AUTOSAR XML (schema 00044)
package /ComponentTypes
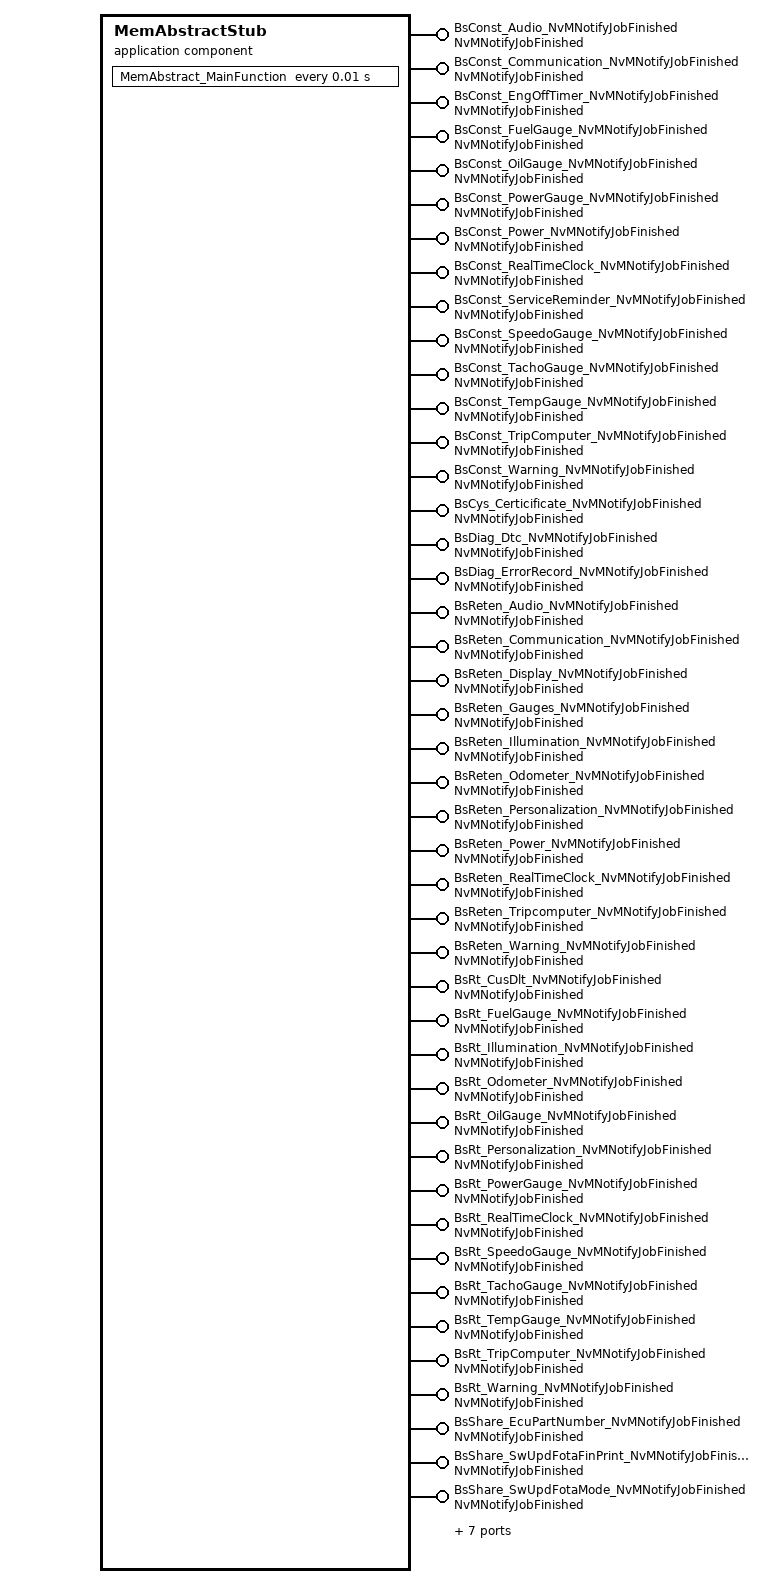
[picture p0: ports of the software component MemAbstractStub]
  application sw component type MemAbstractStub
    51 x provide port, all with server-com-spec{operation=JobFinished, queue-length=1}, provided-interface=NvMNotifyJobFinished:
      BsConst_Audio_NvMNotifyJobFinished
      BsConst_Communication_NvMNotifyJobFinished
      BsConst_EngOffTimer_NvMNotifyJobFinished
      BsConst_FuelGauge_NvMNotifyJobFinished
      BsConst_OilGauge_NvMNotifyJobFinished
      BsConst_PowerGauge_NvMNotifyJobFinished
      BsConst_Power_NvMNotifyJobFinished
      BsConst_RealTimeClock_NvMNotifyJobFinished
      BsConst_ServiceReminder_NvMNotifyJobFinished
      BsConst_SpeedoGauge_NvMNotifyJobFinished
      BsConst_TachoGauge_NvMNotifyJobFinished
      BsConst_TempGauge_NvMNotifyJobFinished
      BsConst_TripComputer_NvMNotifyJobFinished
      BsConst_Warning_NvMNotifyJobFinished
      BsCys_Certicificate_NvMNotifyJobFinished
      BsDiag_Dtc_NvMNotifyJobFinished
      BsDiag_ErrorRecord_NvMNotifyJobFinished
      BsReten_Audio_NvMNotifyJobFinished
      BsReten_Communication_NvMNotifyJobFinished
      BsReten_Display_NvMNotifyJobFinished
      BsReten_Gauges_NvMNotifyJobFinished
      BsReten_Illumination_NvMNotifyJobFinished
      BsReten_Odometer_NvMNotifyJobFinished
      BsReten_Personalization_NvMNotifyJobFinished
      BsReten_Power_NvMNotifyJobFinished
      BsReten_RealTimeClock_NvMNotifyJobFinished
      BsReten_Tripcomputer_NvMNotifyJobFinished
      BsReten_Warning_NvMNotifyJobFinished
      BsRt_CusDlt_NvMNotifyJobFinished
      BsRt_FuelGauge_NvMNotifyJobFinished
      BsRt_Illumination_NvMNotifyJobFinished
      BsRt_Odometer_NvMNotifyJobFinished
      BsRt_OilGauge_NvMNotifyJobFinished
      BsRt_Personalization_NvMNotifyJobFinished
      BsRt_PowerGauge_NvMNotifyJobFinished
      BsRt_RealTimeClock_NvMNotifyJobFinished
      BsRt_SpeedoGauge_NvMNotifyJobFinished
      BsRt_TachoGauge_NvMNotifyJobFinished
      BsRt_TempGauge_NvMNotifyJobFinished
      BsRt_TripComputer_NvMNotifyJobFinished
      BsRt_Warning_NvMNotifyJobFinished
      BsShare_EcuPartNumber_NvMNotifyJobFinished
      BsShare_SwUpdFotaFinPrint_NvMNotifyJobFinished
      BsShare_SwUpdFotaMode_NvMNotifyJobFinished
      BsShare_SwUpdFotaStatus_NvMNotifyJobFinished
      BsShare_SwUpdFotadecrypt_NvMNotifyJobFinished
      BsShare_SwUpdReflash_NvMNotifyJobFinished
      BsShare_VehicleConfig_NvMNotifyJobFinished
      BsShare_VisMeet_NvMNotifyJobFinished
      RefCys_Certicificate1_NvMNotifyJobFinished
      RefCys_Certicificate_NvMNotifyJobFinished
    94 x provide/require port:
      BsRt_SpeedoGauge_Element: nv-provide-com-spec{ram-block-init-value=8 x 0, rom-block-init-value=8 x 0, variable=Value}, nv-require-com-spec{init-value=8 x 0, variable=Value}, provided-required-interface=BsRt_SpeedoGauge_Element
      BsConst_Audio_Element: nv-provide-com-spec{ram-block-init-value=128 x 0, rom-block-init-value=128 x 0, variable=Value}, nv-require-com-spec{init-value=128 x 0, variable=Value}, provided-required-interface=BsConst_Audio_Element
      BsConst_EngOffTimer_Element: nv-provide-com-spec{ram-block-init-value=32 x 0, rom-block-init-value=32 x 0, variable=Value}, nv-require-com-spec{init-value=32 x 0, variable=Value}, provided-required-interface=BsConst_EngOffTimer_Element
      BsRt_OilGauge_Element: nv-provide-com-spec{ram-block-init-value=8 x 0, rom-block-init-value=8 x 0, variable=Value}, nv-require-com-spec{init-value=8 x 0, variable=Value}, provided-required-interface=BsRt_OilGauge_Element
      BsShare_EcuPartNumber_Element: nv-provide-com-spec{ram-block-init-value=61 x 0, rom-block-init-value=61 x 0, variable=Value}, nv-require-com-spec{init-value=61 x 0, variable=Value}, provided-required-interface=BsShare_EcuPartNumber_Element
      BsConst_PCB_Temperature_Sensor_Conv: nv-provide-com-spec{ram-block-init-value=[4095, 4095], rom-block-init-value=[4095, 4095], variable=Value}, nv-require-com-spec{init-value=[4095, 4095], variable=Value}, provided-required-interface=BsConst_PCB_Temperature_Sensor_Conv
      BsConst_Compensation_Line_Slope_m_SafeCopy2: nv-provide-com-spec{ram-block-init-value=44433, rom-block-init-value=44433, variable=Value}, nv-require-com-spec{init-value=44433, variable=Value}, provided-required-interface=BsConst_Compensation_Line_Slope_m_SafeCopy2
      BsConst_Temp_Threshold_Hysteresis_Derating_SafeCopy2: nv-provide-com-spec{ram-block-init-value=68, rom-block-init-value=68, variable=Value}, nv-require-com-spec{init-value=68, variable=Value}, provided-required-interface=BsConst_Temp_Threshold_Hysteresis_Derating_SafeCopy2
      BsConst_Compensation_Line_Shift_b: nv-provide-com-spec{ram-block-init-value=11, rom-block-init-value=11, variable=Value}, nv-require-com-spec{init-value=11, variable=Value}, provided-required-interface=BsConst_Compensation_Line_Shift_b
      BsConst_Temperature_Sensor_Conv_SafeCopy2: nv-provide-com-spec{ram-block-init-value=[4095, 4095], rom-block-init-value=[4095, 4095], variable=Value}, nv-require-com-spec{init-value=[4095, 4095], variable=Value}, provided-required-interface=BsConst_Temperature_Sensor_Conv_SafeCopy2
      BsShare_VisteonPartNumber: nv-provide-com-spec{ram-block-init-value=17 x 255, rom-block-init-value=17 x 255, variable=Value}, nv-require-com-spec{init-value=17 x 255, variable=Value}, provided-required-interface=BsShare_VisteonPartNumber
      BsConst_TempGauge_Element: nv-provide-com-spec{ram-block-init-value=64 x 0, rom-block-init-value=64 x 0, variable=Value}, nv-require-com-spec{init-value=64 x 0, variable=Value}, provided-required-interface=BsConst_TempGauge_Element
      BsConst_Lookup_Curve_HotSpot_Coef_X: nv-provide-com-spec{ram-block-init-value=[700, 710, 720, 730, 740, 750, 760], rom-block-init-value=[700, 710, 720, 730, 740, 750, 760], variable=Value}, nv-require-com-spec{init-value=[700, 710, 720, 730, 740, 750, 760], variable=Value}, provided-required-interface=BsConst_Lookup_Curve_HotSpot_Coef_X
      BsConst_Temperature_Sensor_Conv_SafeCopy1: nv-provide-com-spec{ram-block-init-value=[4095, 4095], rom-block-init-value=[4095, 4095], variable=Value}, nv-require-com-spec{init-value=[4095, 4095], variable=Value}, provided-required-interface=BsConst_Temperature_Sensor_Conv_SafeCopy1
      BsReten_Personalization_Element: nv-provide-com-spec{ram-block-init-value=100 x 0, rom-block-init-value=100 x 0, variable=Value}, nv-require-com-spec{init-value=100 x 0, variable=Value}, provided-required-interface=BsReten_Personalization_Element
      BsRt_RealTimeClock_Element: nv-provide-com-spec{ram-block-init-value=48 x 0, rom-block-init-value=48 x 0, variable=Value}, nv-require-com-spec{init-value=48 x 0, variable=Value}, provided-required-interface=BsRt_RealTimeClock_Element
      BsConst_Derating_Backlight_Disable: nv-provide-com-spec{ram-block-init-value=0, rom-block-init-value=0, variable=Value}, nv-require-com-spec{init-value=0, variable=Value}, provided-required-interface=BsConst_Derating_Backlight_Disable
      BsConst_Communication_Element: nv-provide-com-spec{ram-block-init-value=64 x 0, rom-block-init-value=64 x 0, variable=Value}, nv-require-com-spec{init-value=64 x 0, variable=Value}, provided-required-interface=BsConst_Communication_Element
      BsRt_PowerGauge_Element: nv-provide-com-spec{ram-block-init-value=32 x 0, rom-block-init-value=32 x 0, variable=Value}, nv-require-com-spec{init-value=32 x 0, variable=Value}, provided-required-interface=BsRt_PowerGauge_Element
      BsShare_VisMeet_EOLEntry_Element: nv-provide-com-spec{ram-block-init-value=65535, rom-block-init-value=65535, variable=Value}, nv-require-com-spec{init-value=65535, variable=Value}, provided-required-interface=BsShare_VisMeet_EOLEntry_Element
      BsConst_SpeedoGauge_Element: nv-provide-com-spec{ram-block-init-value=64 x 0, rom-block-init-value=64 x 0, variable=Value}, nv-require-com-spec{init-value=64 x 0, variable=Value}, provided-required-interface=BsConst_SpeedoGauge_Element
      BsCys_Certicificate_Element: nv-provide-com-spec{ram-block-init-value=64 x 0, rom-block-init-value=64 x 0, variable=Value}, nv-require-com-spec{init-value=64 x 0, variable=Value}, provided-required-interface=BsCys_Certicificate_Element
      BsReten_Tripcomputer_Element: nv-provide-com-spec{ram-block-init-value=100 x 0, rom-block-init-value=100 x 0, variable=Value}, nv-require-com-spec{init-value=100 x 0, variable=Value}, provided-required-interface=BsReten_Tripcomputer_Element
      BsRt_FuelGauge_Element: nv-provide-com-spec{ram-block-init-value=32 x 0, rom-block-init-value=32 x 0, variable=Value}, nv-require-com-spec{init-value=32 x 0, variable=Value}, provided-required-interface=BsRt_FuelGauge_Element
      BsConst_Lookup_Curve_HotSpot_Coef_Y: nv-provide-com-spec{ram-block-init-value=[8600, 7700, 6700, 5800, 4800, 3900, 3000], rom-block-init-value=[8600, 7700, 6700, 5800, 4800, 3900, 3000], variable=Value}, nv-require-com-spec{init-value=[8600, 7700, 6700, 5800, 4800, 3900, 3000], variable=Value}, provided-required-interface=BsConst_Lookup_Curve_HotSpot_Coef_Y
      BsShare_SwUpdFotadecrypt_Element: nv-provide-com-spec{ram-block-init-value=64 x 0, rom-block-init-value=64 x 0, variable=Value}, nv-require-com-spec{init-value=64 x 0, variable=Value}, provided-required-interface=BsShare_SwUpdFotadecrypt_Element
      BsRt_Personalization_Element: nv-provide-com-spec{ram-block-init-value=128 x 0, rom-block-init-value=128 x 0, variable=Value}, nv-require-com-spec{init-value=128 x 0, variable=Value}, provided-required-interface=BsRt_Personalization_Element
      BsShare_VehicleConfig_Element: nv-provide-com-spec{ram-block-init-value=256 x 0, rom-block-init-value=256 x 0, variable=Value}, nv-require-com-spec{init-value=256 x 0, variable=Value}, provided-required-interface=BsShare_VehicleConfig_Element
      BsConst_RealTimeClock_Element: nv-provide-com-spec{ram-block-init-value=48 x 0, rom-block-init-value=48 x 0, variable=Value}, nv-require-com-spec{init-value=48 x 0, variable=Value}, provided-required-interface=BsConst_RealTimeClock_Element
      BsConst_TripComputer_Element: nv-provide-com-spec{ram-block-init-value=64 x 0, rom-block-init-value=64 x 0, variable=Value}, nv-require-com-spec{init-value=64 x 0, variable=Value}, provided-required-interface=BsConst_TripComputer_Element
      BsRt_Odometer_Element: nv-provide-com-spec{ram-block-init-value=128 x 0, rom-block-init-value=128 x 0, variable=Value}, nv-require-com-spec{init-value=128 x 0, variable=Value}, provided-required-interface=BsRt_Odometer_Element
      BsConst_Temp_Threshold_Hysteresis_Derating: nv-provide-com-spec{ram-block-init-value=68, rom-block-init-value=68, variable=Value}, nv-require-com-spec{init-value=68, variable=Value}, provided-required-interface=BsConst_Temp_Threshold_Hysteresis_Derating
      BsShare_SMTManufacturingDate: nv-provide-com-spec{ram-block-init-value=[1, 1, 0], rom-block-init-value=[1, 1, 0], variable=Value}, nv-require-com-spec{init-value=[1, 1, 0], variable=Value}, provided-required-interface=BsShare_SMTManufacturingDate
      BsRt_TempGauge_Element: nv-provide-com-spec{ram-block-init-value=32 x 0, rom-block-init-value=32 x 0, variable=Value}, nv-require-com-spec{init-value=32 x 0, variable=Value}, provided-required-interface=BsRt_TempGauge_Element
      BsReten_Power_Element: nv-provide-com-spec{ram-block-init-value=100 x 0, rom-block-init-value=100 x 0, variable=Value}, nv-require-com-spec{init-value=100 x 0, variable=Value}, provided-required-interface=BsReten_Power_Element
      BsReten_Gauges_Element: nv-provide-com-spec{ram-block-init-value=100 x 0, rom-block-init-value=100 x 0, variable=Value}, nv-require-com-spec{init-value=100 x 0, variable=Value}, provided-required-interface=BsReten_Gauges_Element
      BsShare_SMTPlantNumber: nv-provide-com-spec{ram-block-init-value=[255, 255, 255], rom-block-init-value=[255, 255, 255], variable=Value}, nv-require-com-spec{init-value=[255, 255, 255], variable=Value}, provided-required-interface=BsShare_SMTPlantNumber
      BsConst_PCB_Temperature_Sensor_Conv_SafeCopy1: nv-provide-com-spec{ram-block-init-value=[4095, 4095], rom-block-init-value=[4095, 4095], variable=Value}, nv-require-com-spec{init-value=[4095, 4095], variable=Value}, provided-required-interface=BsConst_PCB_Temperature_Sensor_Conv_SafeCopy1
      BsConst_Lookup_Curve_HotSpot_Coef_Y_SafeCopy2: nv-provide-com-spec{ram-block-init-value=[8600, 7700, 6700, 5800, 4800, 3900, 3000], rom-block-init-value=[8600, 7700, 6700, 5800, 4800, 3900, 3000], variable=Value}, nv-require-com-spec{init-value=[8600, 7700, 6700, 5800, 4800, 3900, 3000], variable=Value}, provided-required-interface=BsConst_Lookup_Curve_HotSpot_Coef_Y_SafeCopy2
      BsConst_BsConst_Illumination_ReservedByte_SafeCopy2: nv-provide-com-spec{ram-block-init-value=28 x 0, rom-block-init-value=28 x 0, variable=Value}, nv-require-com-spec{init-value=28 x 0, variable=Value}, provided-required-interface=BsConst_BsConst_Illumination_ReservedByte_SafeCopy2
      BsRt_Warning_Element: nv-provide-com-spec{ram-block-init-value=32 x 0, rom-block-init-value=32 x 0, variable=Value}, nv-require-com-spec{init-value=32 x 0, variable=Value}, provided-required-interface=BsRt_Warning_Element
      BsReten_Warning_Element: nv-provide-com-spec{ram-block-init-value=100 x 0, rom-block-init-value=100 x 0, variable=Value}, nv-require-com-spec{init-value=100 x 0, variable=Value}, provided-required-interface=BsReten_Warning_Element
      BsShare_AssemblyPlantNumber: nv-provide-com-spec{ram-block-init-value=[255, 255, 255], rom-block-init-value=[255, 255, 255], variable=Value}, nv-require-com-spec{init-value=[255, 255, 255], variable=Value}, provided-required-interface=BsShare_AssemblyPlantNumber
      BsConst_OilGauge_Element: nv-provide-com-spec{ram-block-init-value=64 x 0, rom-block-init-value=64 x 0, variable=Value}, nv-require-com-spec{init-value=64 x 0, variable=Value}, provided-required-interface=BsConst_OilGauge_Element
      BsRt_Illumination_Element: nv-provide-com-spec{ram-block-init-value=100 x 0, rom-block-init-value=100 x 0, variable=Value}, nv-require-com-spec{init-value=100 x 0, variable=Value}, provided-required-interface=BsRt_Illumination_Element
      RefCys_Certicificate_Element: nv-provide-com-spec{ram-block-init-value=64 x 0, rom-block-init-value=64 x 0, variable=Value}, nv-require-com-spec{init-value=64 x 0, variable=Value}, provided-required-interface=RefCys_Certicificate_Element
      BsShare_VisMeet_Element: nv-provide-com-spec{ram-block-init-value=46 x 0, rom-block-init-value=46 x 0, variable=Value}, nv-require-com-spec{init-value=46 x 0, variable=Value}, provided-required-interface=BsShare_VisMeet_Element
      BsConst_Derating_Backlight_Disable_SafeCopy1: nv-provide-com-spec{ram-block-init-value=0, rom-block-init-value=0, variable=Value}, nv-require-com-spec{init-value=0, variable=Value}, provided-required-interface=BsConst_Derating_Backlight_Disable_SafeCopy1
      BsShare_ProductSerialNumber: nv-provide-com-spec{ram-block-init-value=10 x 255, rom-block-init-value=10 x 255, variable=Value}, nv-require-com-spec{init-value=10 x 255, variable=Value}, provided-required-interface=BsShare_ProductSerialNumber
      BsConst_ServiceReminder_Element: nv-provide-com-spec{ram-block-init-value=48 x 0, rom-block-init-value=48 x 0, variable=Value}, nv-require-com-spec{init-value=48 x 0, variable=Value}, provided-required-interface=BsConst_ServiceReminder_Element
      BsShare_AssemblyManufacturingDate: nv-provide-com-spec{ram-block-init-value=[1, 1, 0], rom-block-init-value=[1, 1, 0], variable=Value}, nv-require-com-spec{init-value=[1, 1, 0], variable=Value}, provided-required-interface=BsShare_AssemblyManufacturingDate
      BsConst_Display_Illum_Max_Level: nv-provide-com-spec{ram-block-init-value=670, rom-block-init-value=670, variable=Value}, nv-require-com-spec{init-value=670, variable=Value}, provided-required-interface=BsConst_Display_Illum_Max_Level
      BsRt_TripComputer_Element: nv-provide-com-spec{ram-block-init-value=64 x 0, rom-block-init-value=64 x 0, variable=Value}, nv-require-com-spec{init-value=64 x 0, variable=Value}, provided-required-interface=BsRt_TripComputer_Element
      BsShare_HWModification: nv-provide-com-spec{ram-block-init-value=0, rom-block-init-value=0, variable=Value}, nv-require-com-spec{init-value=0, variable=Value}, provided-required-interface=BsShare_HWModification
      BsConst_FuelGauge_Element: nv-provide-com-spec{ram-block-init-value=128 x 0, rom-block-init-value=128 x 0, variable=Value}, nv-require-com-spec{init-value=128 x 0, variable=Value}, provided-required-interface=BsConst_FuelGauge_Element
      BsConst_TachoGauge_Element: nv-provide-com-spec{ram-block-init-value=64 x 0, rom-block-init-value=64 x 0, variable=Value}, nv-require-com-spec{init-value=64 x 0, variable=Value}, provided-required-interface=BsConst_TachoGauge_Element
      BsConst_PWM_boost_bypass_duty: nv-provide-com-spec{ram-block-init-value=100, rom-block-init-value=100, variable=Value}, nv-require-com-spec{init-value=100, variable=Value}, provided-required-interface=BsConst_PWM_boost_bypass_duty
      BsShare_SwUpdFotaFinPrint_Element: nv-provide-com-spec{ram-block-init-value=32 x 0, rom-block-init-value=32 x 0, variable=Value}, nv-require-com-spec{init-value=32 x 0, variable=Value}, provided-required-interface=BsShare_SwUpdFotaFinPrint_Element
      BsConst_PWM_boost_bypass_duty_SafeCopy2: nv-provide-com-spec{ram-block-init-value=100, rom-block-init-value=100, variable=Value}, nv-require-com-spec{init-value=100, variable=Value}, provided-required-interface=BsConst_PWM_boost_bypass_duty_SafeCopy2
      BsConst_Temperature_Sensor_Conv: nv-provide-com-spec{ram-block-init-value=[4095, 4095], rom-block-init-value=[4095, 4095], variable=Value}, nv-require-com-spec{init-value=[4095, 4095], variable=Value}, provided-required-interface=BsConst_Temperature_Sensor_Conv
      BsConst_Lookup_Curve_HotSpot_Coef_Y_SafeCopy1: nv-provide-com-spec{ram-block-init-value=[8600, 7700, 6700, 5800, 4800, 3900, 3000], rom-block-init-value=[8600, 7700, 6700, 5800, 4800, 3900, 3000], variable=Value}, nv-require-com-spec{init-value=[8600, 7700, 6700, 5800, 4800, 3900, 3000], variable=Value}, provided-required-interface=BsConst_Lookup_Curve_HotSpot_Coef_Y_SafeCopy1
      BsReten_Odometer_Element: nv-provide-com-spec{ram-block-init-value=100 x 0, rom-block-init-value=100 x 0, variable=Value}, nv-require-com-spec{init-value=100 x 0, variable=Value}, provided-required-interface=BsReten_Odometer_Element
      BsConst_Compensation_Line_Shift_b_SafeCopy1: nv-provide-com-spec{ram-block-init-value=11, rom-block-init-value=11, variable=Value}, nv-require-com-spec{init-value=11, variable=Value}, provided-required-interface=BsConst_Compensation_Line_Shift_b_SafeCopy1
      BsReten_RealTimeClock_Element: nv-provide-com-spec{ram-block-init-value=100 x 0, rom-block-init-value=100 x 0, variable=Value}, nv-require-com-spec{init-value=100 x 0, variable=Value}, provided-required-interface=BsReten_RealTimeClock_Element
      BsConst_Derating_Backlight_Disable_SafeCopy2: nv-provide-com-spec{ram-block-init-value=0, rom-block-init-value=0, variable=Value}, nv-require-com-spec{init-value=0, variable=Value}, provided-required-interface=BsConst_Derating_Backlight_Disable_SafeCopy2
      BsConst_Compensation_Line_Slope_m_SafeCopy1: nv-provide-com-spec{ram-block-init-value=44433, rom-block-init-value=44433, variable=Value}, nv-require-com-spec{init-value=44433, variable=Value}, provided-required-interface=BsConst_Compensation_Line_Slope_m_SafeCopy1
      BsReten_Communication_Element: nv-provide-com-spec{ram-block-init-value=100 x 0, rom-block-init-value=100 x 0, variable=Value}, nv-require-com-spec{init-value=100 x 0, variable=Value}, provided-required-interface=BsReten_Communication_Element
      BsConst_Power_Element: nv-provide-com-spec{ram-block-init-value=32 x 0, rom-block-init-value=32 x 0, variable=Value}, nv-require-com-spec{init-value=32 x 0, variable=Value}, provided-required-interface=BsConst_Power_Element
      BsConst_Compensation_Line_Slope_m: nv-provide-com-spec{ram-block-init-value=44433, rom-block-init-value=44433, variable=Value}, nv-require-com-spec{init-value=44433, variable=Value}, provided-required-interface=BsConst_Compensation_Line_Slope_m
      BsShare_SwUpdFotaStatus_Element: nv-provide-com-spec{ram-block-init-value=48 x 0, rom-block-init-value=48 x 0, variable=Value}, nv-require-com-spec{init-value=48 x 0, variable=Value}, provided-required-interface=BsShare_SwUpdFotaStatus_Element
      BsDiag_ErrorRecord_Element: nv-provide-com-spec{ram-block-init-value=1024 x 0, rom-block-init-value=1024 x 0, variable=Value}, nv-require-com-spec{init-value=1024 x 0, variable=Value}, provided-required-interface=BsDiag_ErrorRecord_Element
      BsConst_Temp_Threshold_Hysteresis_Derating_SafeCopy1: nv-provide-com-spec{ram-block-init-value=68, rom-block-init-value=68, variable=Value}, nv-require-com-spec{init-value=68, variable=Value}, provided-required-interface=BsConst_Temp_Threshold_Hysteresis_Derating_SafeCopy1
      RefCys_Certicificate1_Element: nv-provide-com-spec{ram-block-init-value=64 x 0, rom-block-init-value=64 x 0, variable=Value}, nv-require-com-spec{init-value=64 x 0, variable=Value}, provided-required-interface=RefCys_Certicificate1_Element
      BsDiag_Dtc_Element: nv-provide-com-spec{ram-block-init-value=2048 x 0, rom-block-init-value=2048 x 0, variable=Value}, nv-require-com-spec{init-value=2048 x 0, variable=Value}, provided-required-interface=BsDiag_Dtc_Element
      BsConst_Compensation_Line_Shift_b_SafeCopy2: nv-provide-com-spec{ram-block-init-value=11, rom-block-init-value=11, variable=Value}, nv-require-com-spec{init-value=11, variable=Value}, provided-required-interface=BsConst_Compensation_Line_Shift_b_SafeCopy2
      BsConst_Display_Illum_Max_Level_SafeCopy2: nv-provide-com-spec{ram-block-init-value=670, rom-block-init-value=670, variable=Value}, nv-require-com-spec{init-value=670, variable=Value}, provided-required-interface=BsConst_Display_Illum_Max_Level_SafeCopy2
      BsRt_CusDlt_Element: nv-provide-com-spec{ram-block-init-value=128 x 0, rom-block-init-value=128 x 0, variable=Value}, nv-require-com-spec{init-value=128 x 0, variable=Value}, provided-required-interface=BsRt_CusDlt_Element
      BsReten_Audio_Element: nv-provide-com-spec{ram-block-init-value=100 x 0, rom-block-init-value=100 x 0, variable=Value}, nv-require-com-spec{init-value=100 x 0, variable=Value}, provided-required-interface=BsReten_Audio_Element
      BsRt_TachoGauge_Element: nv-provide-com-spec{ram-block-init-value=16 x 0, rom-block-init-value=16 x 0, variable=Value}, nv-require-com-spec{init-value=16 x 0, variable=Value}, provided-required-interface=BsRt_TachoGauge_Element
      BsReten_Illumination_Element: nv-provide-com-spec{ram-block-init-value=100 x 0, rom-block-init-value=100 x 0, variable=Value}, nv-require-com-spec{init-value=100 x 0, variable=Value}, provided-required-interface=BsReten_Illumination_Element
      BsConst_BsConst_Illumination_ReservedByte_SafeCopy1: nv-provide-com-spec{ram-block-init-value=28 x 0, rom-block-init-value=28 x 0, variable=Value}, nv-require-com-spec{init-value=28 x 0, variable=Value}, provided-required-interface=BsConst_BsConst_Illumination_ReservedByte_SafeCopy1
      BsConst_Lookup_Curve_HotSpot_Coef_X_SafeCopy1: nv-provide-com-spec{ram-block-init-value=[700, 710, 720, 730, 740, 750, 760], rom-block-init-value=[700, 710, 720, 730, 740, 750, 760], variable=Value}, nv-require-com-spec{init-value=[700, 710, 720, 730, 740, 750, 760], variable=Value}, provided-required-interface=BsConst_Lookup_Curve_HotSpot_Coef_X_SafeCopy1
      BsConst_BsConst_Illumination_ReservedByte: nv-provide-com-spec{ram-block-init-value=28 x 0, rom-block-init-value=28 x 0, variable=Value}, nv-require-com-spec{init-value=28 x 0, variable=Value}, provided-required-interface=BsConst_BsConst_Illumination_ReservedByte
      BsConst_Warning_Element: nv-provide-com-spec{ram-block-init-value=64 x 0, rom-block-init-value=64 x 0, variable=Value}, nv-require-com-spec{init-value=64 x 0, variable=Value}, provided-required-interface=BsConst_Warning_Element
      BsShare_SwUpdFotaMode_Element: nv-provide-com-spec{ram-block-init-value=16 x 0, rom-block-init-value=16 x 0, variable=Value}, nv-require-com-spec{init-value=16 x 0, variable=Value}, provided-required-interface=BsShare_SwUpdFotaMode_Element
      BsReten_Display_Element: nv-provide-com-spec{ram-block-init-value=100 x 0, rom-block-init-value=100 x 0, variable=Value}, nv-require-com-spec{init-value=100 x 0, variable=Value}, provided-required-interface=BsReten_Display_Element
      BsConst_PCB_Temperature_Sensor_Conv_SafeCopy2: nv-provide-com-spec{ram-block-init-value=[4095, 4095], rom-block-init-value=[4095, 4095], variable=Value}, nv-require-com-spec{init-value=[4095, 4095], variable=Value}, provided-required-interface=BsConst_PCB_Temperature_Sensor_Conv_SafeCopy2
      BsShare_SwUpdReflash_Element: nv-provide-com-spec{ram-block-init-value=8 x 0, rom-block-init-value=8 x 0, variable=Value}, nv-require-com-spec{init-value=8 x 0, variable=Value}, provided-required-interface=BsShare_SwUpdReflash_Element
      BsShare_VisteonPCBPartNumber: nv-provide-com-spec{ram-block-init-value=17 x 255, rom-block-init-value=17 x 255, variable=Value}, nv-require-com-spec{init-value=17 x 255, variable=Value}, provided-required-interface=BsShare_VisteonPCBPartNumber
      BsConst_Lookup_Curve_HotSpot_Coef_X_SafeCopy2: nv-provide-com-spec{ram-block-init-value=[700, 710, 720, 730, 740, 750, 760], rom-block-init-value=[700, 710, 720, 730, 740, 750, 760], variable=Value}, nv-require-com-spec{init-value=[700, 710, 720, 730, 740, 750, 760], variable=Value}, provided-required-interface=BsConst_Lookup_Curve_HotSpot_Coef_X_SafeCopy2
      BsConst_Display_Illum_Max_Level_SafeCopy1: nv-provide-com-spec{ram-block-init-value=670, rom-block-init-value=670, variable=Value}, nv-require-com-spec{init-value=670, variable=Value}, provided-required-interface=BsConst_Display_Illum_Max_Level_SafeCopy1
      BsConst_PWM_boost_bypass_duty_SafeCopy1: nv-provide-com-spec{ram-block-init-value=100, rom-block-init-value=100, variable=Value}, nv-require-com-spec{init-value=100, variable=Value}, provided-required-interface=BsConst_PWM_boost_bypass_duty_SafeCopy1
      BsShare_PCBSerialNumber: nv-provide-com-spec{ram-block-init-value=9 x 255, rom-block-init-value=9 x 255, variable=Value}, nv-require-com-spec{init-value=9 x 255, variable=Value}, provided-required-interface=BsShare_PCBSerialNumber
      BsConst_PowerGauge_Element: nv-provide-com-spec{ram-block-init-value=64 x 0, rom-block-init-value=64 x 0, variable=Value}, nv-require-com-spec{init-value=64 x 0, variable=Value}, provided-required-interface=BsConst_PowerGauge_Element
    behavior MemAbstractStub_InternalBehavior
      timing event TMT_MemAbstract_MainFunction: start-on-event=MemAbstract_MainFunction, period=0.01
      51 x operation invoked event:
        OIT_MemAbstractMdl_NotifyJobEnd_BsConst_Audio_NvMNotifyJobFinished_JobFinished: start-on-event=MemAbstractMdl_NotifyJobEnd_BsConst_Audio, operation=BsConst_Audio_NvMNotifyJobFinished.JobFinished
        OIT_MemAbstractMdl_NotifyJobEnd_BsConst_Communication_NvMNotifyJobFinished_JobFinished: start-on-event=MemAbstractMdl_NotifyJobEnd_BsConst_Communication, operation=BsConst_Communication_NvMNotifyJobFinished.JobFinished
        OIT_MemAbstractMdl_NotifyJobEnd_BsConst_EngOffTimer_NvMNotifyJobFinished_JobFinished: start-on-event=MemAbstractMdl_NotifyJobEnd_BsConst_EngOffTimer, operation=BsConst_EngOffTimer_NvMNotifyJobFinished.JobFinished
        OIT_MemAbstractMdl_NotifyJobEnd_BsConst_FuelGauge_NvMNotifyJobFinished_JobFinished: start-on-event=MemAbstractMdl_NotifyJobEnd_BsConst_FuelGauge, operation=BsConst_FuelGauge_NvMNotifyJobFinished.JobFinished
        OIT_MemAbstractMdl_NotifyJobEnd_BsConst_OilGauge_NvMNotifyJobFinished_JobFinished: start-on-event=MemAbstractMdl_NotifyJobEnd_BsConst_OilGauge, operation=BsConst_OilGauge_NvMNotifyJobFinished.JobFinished
        OIT_MemAbstractMdl_NotifyJobEnd_BsConst_Power_NvMNotifyJobFinished_JobFinished: start-on-event=MemAbstractMdl_NotifyJobEnd_BsConst_Power, operation=BsConst_Power_NvMNotifyJobFinished.JobFinished
        OIT_MemAbstractMdl_NotifyJobEnd_BsConst_PowerGauge_NvMNotifyJobFinished_JobFinished: start-on-event=MemAbstractMdl_NotifyJobEnd_BsConst_PowerGauge, operation=BsConst_PowerGauge_NvMNotifyJobFinished.JobFinished
        OIT_MemAbstractMdl_NotifyJobEnd_BsConst_RealTimeClock_NvMNotifyJobFinished_JobFinished: start-on-event=MemAbstractMdl_NotifyJobEnd_BsConst_RealTimeClock, operation=BsConst_RealTimeClock_NvMNotifyJobFinished.JobFinished
        OIT_MemAbstractMdl_NotifyJobEnd_BsConst_ServiceReminder_NvMNotifyJobFinished_JobFinished: start-on-event=MemAbstractMdl_NotifyJobEnd_BsConst_ServiceReminder, operation=BsConst_ServiceReminder_NvMNotifyJobFinished.JobFinished
        OIT_MemAbstractMdl_NotifyJobEnd_BsConst_SpeedoGauge_NvMNotifyJobFinished_JobFinished: start-on-event=MemAbstractMdl_NotifyJobEnd_BsConst_SpeedoGauge, operation=BsConst_SpeedoGauge_NvMNotifyJobFinished.JobFinished
        OIT_MemAbstractMdl_NotifyJobEnd_BsConst_TachoGauge_NvMNotifyJobFinished_JobFinished: start-on-event=MemAbstractMdl_NotifyJobEnd_BsConst_TachoGauge, operation=BsConst_TachoGauge_NvMNotifyJobFinished.JobFinished
        OIT_MemAbstractMdl_NotifyJobEnd_BsConst_TempGauge_NvMNotifyJobFinished_JobFinished: start-on-event=MemAbstractMdl_NotifyJobEnd_BsConst_TempGauge, operation=BsConst_TempGauge_NvMNotifyJobFinished.JobFinished
        OIT_MemAbstractMdl_NotifyJobEnd_BsConst_TripComputer_NvMNotifyJobFinished_JobFinished: start-on-event=MemAbstractMdl_NotifyJobEnd_BsConst_TripComputer, operation=BsConst_TripComputer_NvMNotifyJobFinished.JobFinished
        OIT_MemAbstractMdl_NotifyJobEnd_BsConst_Warning_NvMNotifyJobFinished_JobFinished: start-on-event=MemAbstractMdl_NotifyJobEnd_BsConst_Warning, operation=BsConst_Warning_NvMNotifyJobFinished.JobFinished
        OIT_MemAbstractMdl_NotifyJobEnd_BsCys_Certicificate_NvMNotifyJobFinished_JobFinished: start-on-event=MemAbstractMdl_NotifyJobEnd_BsCys_Certicificate, operation=BsCys_Certicificate_NvMNotifyJobFinished.JobFinished
        OIT_MemAbstractMdl_NotifyJobEnd_BsDiag_Dtc_NvMNotifyJobFinished_JobFinished: start-on-event=MemAbstractMdl_NotifyJobEnd_BsDiag_Dtc, operation=BsDiag_Dtc_NvMNotifyJobFinished.JobFinished
        OIT_MemAbstractMdl_NotifyJobEnd_BsDiag_ErrorRecord_NvMNotifyJobFinished_JobFinished: start-on-event=MemAbstractMdl_NotifyJobEnd_BsDiag_ErrorRecord, operation=BsDiag_ErrorRecord_NvMNotifyJobFinished.JobFinished
        OIT_MemAbstractMdl_NotifyJobEnd_BsReten_Audio_NvMNotifyJobFinished_JobFinished: start-on-event=MemAbstractMdl_NotifyJobEnd_BsReten_Audio, operation=BsReten_Audio_NvMNotifyJobFinished.JobFinished
        OIT_MemAbstractMdl_NotifyJobEnd_BsReten_Communication_NvMNotifyJobFinished_JobFinished: start-on-event=MemAbstractMdl_NotifyJobEnd_BsReten_Communication, operation=BsReten_Communication_NvMNotifyJobFinished.JobFinished
        OIT_MemAbstractMdl_NotifyJobEnd_BsReten_Display_NvMNotifyJobFinished_JobFinished: start-on-event=MemAbstractMdl_NotifyJobEnd_BsReten_Display, operation=BsReten_Display_NvMNotifyJobFinished.JobFinished
        OIT_MemAbstractMdl_NotifyJobEnd_BsReten_Gauges_NvMNotifyJobFinished_JobFinished: start-on-event=MemAbstractMdl_NotifyJobEnd_BsReten_Gauges, operation=BsReten_Gauges_NvMNotifyJobFinished.JobFinished
        OIT_MemAbstractMdl_NotifyJobEnd_BsReten_Illumination_NvMNotifyJobFinished_JobFinished: start-on-event=MemAbstractMdl_NotifyJobEnd_BsReten_Illumination, operation=BsReten_Illumination_NvMNotifyJobFinished.JobFinished
        OIT_MemAbstractMdl_NotifyJobEnd_BsReten_Odometer_NvMNotifyJobFinished_JobFinished: start-on-event=MemAbstractMdl_NotifyJobEnd_BsReten_Odometer, operation=BsReten_Odometer_NvMNotifyJobFinished.JobFinished
        OIT_MemAbstractMdl_NotifyJobEnd_BsReten_Personalization_NvMNotifyJobFinished_JobFinished: start-on-event=MemAbstractMdl_NotifyJobEnd_BsReten_Personalization, operation=BsReten_Personalization_NvMNotifyJobFinished.JobFinished
        OIT_MemAbstractMdl_NotifyJobEnd_BsReten_Power_NvMNotifyJobFinished_JobFinished: start-on-event=MemAbstractMdl_NotifyJobEnd_BsReten_Power, operation=BsReten_Power_NvMNotifyJobFinished.JobFinished
        OIT_MemAbstractMdl_NotifyJobEnd_BsReten_RealTimeClock_NvMNotifyJobFinished_JobFinished: start-on-event=MemAbstractMdl_NotifyJobEnd_BsReten_RealTimeClock, operation=BsReten_RealTimeClock_NvMNotifyJobFinished.JobFinished
        OIT_MemAbstractMdl_NotifyJobEnd_BsReten_Tripcomputer_NvMNotifyJobFinished_JobFinished: start-on-event=MemAbstractMdl_NotifyJobEnd_BsReten_Tripcomputer, operation=BsReten_Tripcomputer_NvMNotifyJobFinished.JobFinished
        OIT_MemAbstractMdl_NotifyJobEnd_BsReten_Warning_NvMNotifyJobFinished_JobFinished: start-on-event=MemAbstractMdl_NotifyJobEnd_BsReten_Warning, operation=BsReten_Warning_NvMNotifyJobFinished.JobFinished
        OIT_MemAbstractMdl_NotifyJobEnd_BsRt_CusDlt_NvMNotifyJobFinished_JobFinished: start-on-event=MemAbstractMdl_NotifyJobEnd_BsRt_CusDlt, operation=BsRt_CusDlt_NvMNotifyJobFinished.JobFinished
        OIT_MemAbstractMdl_NotifyJobEnd_BsRt_FuelGauge_NvMNotifyJobFinished_JobFinished: start-on-event=MemAbstractMdl_NotifyJobEnd_BsRt_FuelGauge, operation=BsRt_FuelGauge_NvMNotifyJobFinished.JobFinished
        OIT_MemAbstractMdl_NotifyJobEnd_BsRt_Illumination_NvMNotifyJobFinished_JobFinished: start-on-event=MemAbstractMdl_NotifyJobEnd_BsRt_Illumination, operation=BsRt_Illumination_NvMNotifyJobFinished.JobFinished
        OIT_MemAbstractMdl_NotifyJobEnd_BsRt_Odometer_NvMNotifyJobFinished_JobFinished: start-on-event=MemAbstractMdl_NotifyJobEnd_BsRt_Odometer, operation=BsRt_Odometer_NvMNotifyJobFinished.JobFinished
        OIT_MemAbstractMdl_NotifyJobEnd_BsRt_OilGauge_NvMNotifyJobFinished_JobFinished: start-on-event=MemAbstractMdl_NotifyJobEnd_BsRt_OilGauge, operation=BsRt_OilGauge_NvMNotifyJobFinished.JobFinished
        OIT_MemAbstractMdl_NotifyJobEnd_BsRt_Personalization_NvMNotifyJobFinished_JobFinished: start-on-event=MemAbstractMdl_NotifyJobEnd_BsRt_Personalization, operation=BsRt_Personalization_NvMNotifyJobFinished.JobFinished
        OIT_MemAbstractMdl_NotifyJobEnd_BsRt_PowerGauge_NvMNotifyJobFinished_JobFinished: start-on-event=MemAbstractMdl_NotifyJobEnd_BsRt_PowerGauge, operation=BsRt_PowerGauge_NvMNotifyJobFinished.JobFinished
        OIT_MemAbstractMdl_NotifyJobEnd_BsRt_RealTimeClock_NvMNotifyJobFinished_JobFinished: start-on-event=MemAbstractMdl_NotifyJobEnd_BsRt_RealTimeClock, operation=BsRt_RealTimeClock_NvMNotifyJobFinished.JobFinished
        OIT_MemAbstractMdl_NotifyJobEnd_BsRt_SpeedoGauge_NvMNotifyJobFinished_JobFinished: start-on-event=MemAbstractMdl_NotifyJobEnd_BsRt_SpeedoGauge, operation=BsRt_SpeedoGauge_NvMNotifyJobFinished.JobFinished
        OIT_MemAbstractMdl_NotifyJobEnd_BsRt_TachoGauge_NvMNotifyJobFinished_JobFinished: start-on-event=MemAbstractMdl_NotifyJobEnd_BsRt_TachoGauge, operation=BsRt_TachoGauge_NvMNotifyJobFinished.JobFinished
        OIT_MemAbstractMdl_NotifyJobEnd_BsRt_TempGauge_NvMNotifyJobFinished_JobFinished: start-on-event=MemAbstractMdl_NotifyJobEnd_BsRt_TempGauge, operation=BsRt_TempGauge_NvMNotifyJobFinished.JobFinished
        OIT_MemAbstractMdl_NotifyJobEnd_BsRt_TripComputer_NvMNotifyJobFinished_JobFinished: start-on-event=MemAbstractMdl_NotifyJobEnd_BsRt_TripComputer, operation=BsRt_TripComputer_NvMNotifyJobFinished.JobFinished
        OIT_MemAbstractMdl_NotifyJobEnd_BsRt_Warning_NvMNotifyJobFinished_JobFinished: start-on-event=MemAbstractMdl_NotifyJobEnd_BsRt_Warning, operation=BsRt_Warning_NvMNotifyJobFinished.JobFinished
        OIT_MemAbstractMdl_NotifyJobEnd_BsShare_EcuPartNumber_NvMNotifyJobFinished_JobFinished: start-on-event=MemAbstractMdl_NotifyJobEnd_BsShare_EcuPartNumber, operation=BsShare_EcuPartNumber_NvMNotifyJobFinished.JobFinished
        OIT_MemAbstractMdl_NotifyJobEnd_BsShare_SwUpdFotaFinPrint_NvMNotifyJobFinished_JobFinished: start-on-event=MemAbstractMdl_NotifyJobEnd_BsShare_SwUpdFotaFinPrint, operation=BsShare_SwUpdFotaFinPrint_NvMNotifyJobFinished.JobFinished
        OIT_MemAbstractMdl_NotifyJobEnd_BsShare_SwUpdFotaMode_NvMNotifyJobFinished_JobFinished: start-on-event=MemAbstractMdl_NotifyJobEnd_BsShare_SwUpdFotaMode, operation=BsShare_SwUpdFotaMode_NvMNotifyJobFinished.JobFinished
        OIT_MemAbstractMdl_NotifyJobEnd_BsShare_SwUpdFotaStatus_NvMNotifyJobFinished_JobFinished: start-on-event=MemAbstractMdl_NotifyJobEnd_BsShare_SwUpdFotaStatus, operation=BsShare_SwUpdFotaStatus_NvMNotifyJobFinished.JobFinished
        OIT_MemAbstractMdl_NotifyJobEnd_BsShare_SwUpdFotadecrypt_NvMNotifyJobFinished_JobFinished: start-on-event=MemAbstractMdl_NotifyJobEnd_BsShare_SwUpdFotadecrypt, operation=BsShare_SwUpdFotadecrypt_NvMNotifyJobFinished.JobFinished
        OIT_MemAbstractMdl_NotifyJobEnd_BsShare_SwUpdReflash_NvMNotifyJobFinished_JobFinished: start-on-event=MemAbstractMdl_NotifyJobEnd_BsShare_SwUpdReflash, operation=BsShare_SwUpdReflash_NvMNotifyJobFinished.JobFinished
        OIT_MemAbstractMdl_NotifyJobEnd_BsShare_VehicleConfig_NvMNotifyJobFinished_JobFinished: start-on-event=MemAbstractMdl_NotifyJobEnd_BsShare_VehicleConfig, operation=BsShare_VehicleConfig_NvMNotifyJobFinished.JobFinished
        OIT_MemAbstractMdl_NotifyJobEnd_BsShare_VisMeet_NvMNotifyJobFinished_JobFinished: start-on-event=MemAbstractMdl_NotifyJobEnd_BsShare_VisMeet, operation=BsShare_VisMeet_NvMNotifyJobFinished.JobFinished
        OIT_MemAbstractMdl_NotifyJobEnd_RefCys_Certicificate_NvMNotifyJobFinished_JobFinished: start-on-event=MemAbstractMdl_NotifyJobEnd_RefCys_Certicificate, operation=RefCys_Certicificate_NvMNotifyJobFinished.JobFinished
        OIT_MemAbstractMdl_NotifyJobEnd_RefCys_Certicificate1_NvMNotifyJobFinished_JobFinished: start-on-event=MemAbstractMdl_NotifyJobEnd_RefCys_Certicificate1, operation=RefCys_Certicificate1_NvMNotifyJobFinished.JobFinished
      52 x runnable:
        MemAbstract_MainFunction
          data-receive-point-by-arguments:
            94 x access:
              REC_BsConst_Audio_Element_Value: accessed-variable=BsConst_Audio_Element.Value
              REC_BsConst_BsConst_Illumination_ReservedByte_Value: accessed-variable=BsConst_BsConst_Illumination_ReservedByte.Value
              REC_BsConst_BsConst_Illumination_ReservedByte_SafeCopy1_Value: accessed-variable=BsConst_BsConst_Illumination_ReservedByte_SafeCopy1.Value
              REC_BsConst_BsConst_Illumination_ReservedByte_SafeCopy2_Value: accessed-variable=BsConst_BsConst_Illumination_ReservedByte_SafeCopy2.Value
              REC_BsConst_Communication_Element_Value: accessed-variable=BsConst_Communication_Element.Value
              REC_BsConst_Compensation_Line_Shift_b_Value: accessed-variable=BsConst_Compensation_Line_Shift_b.Value
              REC_BsConst_Compensation_Line_Shift_b_SafeCopy1_Value: accessed-variable=BsConst_Compensation_Line_Shift_b_SafeCopy1.Value
              REC_BsConst_Compensation_Line_Shift_b_SafeCopy2_Value: accessed-variable=BsConst_Compensation_Line_Shift_b_SafeCopy2.Value
              REC_BsConst_Compensation_Line_Slope_m_Value: accessed-variable=BsConst_Compensation_Line_Slope_m.Value
              REC_BsConst_Compensation_Line_Slope_m_SafeCopy1_Value: accessed-variable=BsConst_Compensation_Line_Slope_m_SafeCopy1.Value
              REC_BsConst_Compensation_Line_Slope_m_SafeCopy2_Value: accessed-variable=BsConst_Compensation_Line_Slope_m_SafeCopy2.Value
              REC_BsConst_Derating_Backlight_Disable_Value: accessed-variable=BsConst_Derating_Backlight_Disable.Value
              REC_BsConst_Derating_Backlight_Disable_SafeCopy1_Value: accessed-variable=BsConst_Derating_Backlight_Disable_SafeCopy1.Value
              REC_BsConst_Derating_Backlight_Disable_SafeCopy2_Value: accessed-variable=BsConst_Derating_Backlight_Disable_SafeCopy2.Value
              REC_BsConst_Display_Illum_Max_Level_Value: accessed-variable=BsConst_Display_Illum_Max_Level.Value
              REC_BsConst_Display_Illum_Max_Level_SafeCopy1_Value: accessed-variable=BsConst_Display_Illum_Max_Level_SafeCopy1.Value
              REC_BsConst_Display_Illum_Max_Level_SafeCopy2_Value: accessed-variable=BsConst_Display_Illum_Max_Level_SafeCopy2.Value
              REC_BsConst_EngOffTimer_Element_Value: accessed-variable=BsConst_EngOffTimer_Element.Value
              REC_BsConst_FuelGauge_Element_Value: accessed-variable=BsConst_FuelGauge_Element.Value
              REC_BsConst_Lookup_Curve_HotSpot_Coef_X_Value: accessed-variable=BsConst_Lookup_Curve_HotSpot_Coef_X.Value
              REC_BsConst_Lookup_Curve_HotSpot_Coef_X_SafeCopy1_Value: accessed-variable=BsConst_Lookup_Curve_HotSpot_Coef_X_SafeCopy1.Value
              REC_BsConst_Lookup_Curve_HotSpot_Coef_X_SafeCopy2_Value: accessed-variable=BsConst_Lookup_Curve_HotSpot_Coef_X_SafeCopy2.Value
              REC_BsConst_Lookup_Curve_HotSpot_Coef_Y_Value: accessed-variable=BsConst_Lookup_Curve_HotSpot_Coef_Y.Value
              REC_BsConst_Lookup_Curve_HotSpot_Coef_Y_SafeCopy1_Value: accessed-variable=BsConst_Lookup_Curve_HotSpot_Coef_Y_SafeCopy1.Value
              REC_BsConst_Lookup_Curve_HotSpot_Coef_Y_SafeCopy2_Value: accessed-variable=BsConst_Lookup_Curve_HotSpot_Coef_Y_SafeCopy2.Value
              REC_BsConst_OilGauge_Element_Value: accessed-variable=BsConst_OilGauge_Element.Value
              REC_BsConst_PCB_Temperature_Sensor_Conv_Value: accessed-variable=BsConst_PCB_Temperature_Sensor_Conv.Value
              REC_BsConst_PCB_Temperature_Sensor_Conv_SafeCopy1_Value: accessed-variable=BsConst_PCB_Temperature_Sensor_Conv_SafeCopy1.Value
              REC_BsConst_PCB_Temperature_Sensor_Conv_SafeCopy2_Value: accessed-variable=BsConst_PCB_Temperature_Sensor_Conv_SafeCopy2.Value
              REC_BsConst_PWM_boost_bypass_duty_Value: accessed-variable=BsConst_PWM_boost_bypass_duty.Value
              REC_BsConst_PWM_boost_bypass_duty_SafeCopy1_Value: accessed-variable=BsConst_PWM_boost_bypass_duty_SafeCopy1.Value
              REC_BsConst_PWM_boost_bypass_duty_SafeCopy2_Value: accessed-variable=BsConst_PWM_boost_bypass_duty_SafeCopy2.Value
              REC_BsConst_PowerGauge_Element_Value: accessed-variable=BsConst_PowerGauge_Element.Value
              REC_BsConst_Power_Element_Value: accessed-variable=BsConst_Power_Element.Value
              REC_BsConst_RealTimeClock_Element_Value: accessed-variable=BsConst_RealTimeClock_Element.Value
              REC_BsConst_ServiceReminder_Element_Value: accessed-variable=BsConst_ServiceReminder_Element.Value
              REC_BsConst_SpeedoGauge_Element_Value: accessed-variable=BsConst_SpeedoGauge_Element.Value
              REC_BsConst_TachoGauge_Element_Value: accessed-variable=BsConst_TachoGauge_Element.Value
              REC_BsConst_TempGauge_Element_Value: accessed-variable=BsConst_TempGauge_Element.Value
              REC_BsConst_Temp_Threshold_Hysteresis_Derating_Value: accessed-variable=BsConst_Temp_Threshold_Hysteresis_Derating.Value
              REC_BsConst_Temp_Threshold_Hysteresis_Derating_SafeCopy1_Value: accessed-variable=BsConst_Temp_Threshold_Hysteresis_Derating_SafeCopy1.Value
              REC_BsConst_Temp_Threshold_Hysteresis_Derating_SafeCopy2_Value: accessed-variable=BsConst_Temp_Threshold_Hysteresis_Derating_SafeCopy2.Value
              REC_BsConst_Temperature_Sensor_Conv_Value: accessed-variable=BsConst_Temperature_Sensor_Conv.Value
              REC_BsConst_Temperature_Sensor_Conv_SafeCopy1_Value: accessed-variable=BsConst_Temperature_Sensor_Conv_SafeCopy1.Value
              REC_BsConst_Temperature_Sensor_Conv_SafeCopy2_Value: accessed-variable=BsConst_Temperature_Sensor_Conv_SafeCopy2.Value
              REC_BsConst_TripComputer_Element_Value: accessed-variable=BsConst_TripComputer_Element.Value
              REC_BsConst_Warning_Element_Value: accessed-variable=BsConst_Warning_Element.Value
              REC_BsCys_Certicificate_Element_Value: accessed-variable=BsCys_Certicificate_Element.Value
              REC_BsDiag_Dtc_Element_Value: accessed-variable=BsDiag_Dtc_Element.Value
              REC_BsDiag_ErrorRecord_Element_Value: accessed-variable=BsDiag_ErrorRecord_Element.Value
              REC_BsReten_Audio_Element_Value: accessed-variable=BsReten_Audio_Element.Value
              REC_BsReten_Communication_Element_Value: accessed-variable=BsReten_Communication_Element.Value
              REC_BsReten_Display_Element_Value: accessed-variable=BsReten_Display_Element.Value
              REC_BsReten_Gauges_Element_Value: accessed-variable=BsReten_Gauges_Element.Value
              REC_BsReten_Illumination_Element_Value: accessed-variable=BsReten_Illumination_Element.Value
              REC_BsReten_Odometer_Element_Value: accessed-variable=BsReten_Odometer_Element.Value
              REC_BsReten_Personalization_Element_Value: accessed-variable=BsReten_Personalization_Element.Value
              REC_BsReten_Power_Element_Value: accessed-variable=BsReten_Power_Element.Value
              REC_BsReten_RealTimeClock_Element_Value: accessed-variable=BsReten_RealTimeClock_Element.Value
              REC_BsReten_Tripcomputer_Element_Value: accessed-variable=BsReten_Tripcomputer_Element.Value
              REC_BsReten_Warning_Element_Value: accessed-variable=BsReten_Warning_Element.Value
              REC_BsRt_CusDlt_Element_Value: accessed-variable=BsRt_CusDlt_Element.Value
              REC_BsRt_FuelGauge_Element_Value: accessed-variable=BsRt_FuelGauge_Element.Value
              REC_BsRt_Illumination_Element_Value: accessed-variable=BsRt_Illumination_Element.Value
              REC_BsRt_Odometer_Element_Value: accessed-variable=BsRt_Odometer_Element.Value
              REC_BsRt_OilGauge_Element_Value: accessed-variable=BsRt_OilGauge_Element.Value
              REC_BsRt_Personalization_Element_Value: accessed-variable=BsRt_Personalization_Element.Value
              REC_BsRt_PowerGauge_Element_Value: accessed-variable=BsRt_PowerGauge_Element.Value
              REC_BsRt_RealTimeClock_Element_Value: accessed-variable=BsRt_RealTimeClock_Element.Value
              REC_BsRt_SpeedoGauge_Element_Value: accessed-variable=BsRt_SpeedoGauge_Element.Value
              REC_BsRt_TachoGauge_Element_Value: accessed-variable=BsRt_TachoGauge_Element.Value
              REC_BsRt_TempGauge_Element_Value: accessed-variable=BsRt_TempGauge_Element.Value
              REC_BsRt_TripComputer_Element_Value: accessed-variable=BsRt_TripComputer_Element.Value
              REC_BsRt_Warning_Element_Value: accessed-variable=BsRt_Warning_Element.Value
              REC_BsShare_AssemblyManufacturingDate_Value: accessed-variable=BsShare_AssemblyManufacturingDate.Value
              REC_BsShare_AssemblyPlantNumber_Value: accessed-variable=BsShare_AssemblyPlantNumber.Value
              REC_BsShare_EcuPartNumber_Element_Value: accessed-variable=BsShare_EcuPartNumber_Element.Value
              REC_BsShare_HWModification_Value: accessed-variable=BsShare_HWModification.Value
              REC_BsShare_PCBSerialNumber_Value: accessed-variable=BsShare_PCBSerialNumber.Value
              REC_BsShare_ProductSerialNumber_Value: accessed-variable=BsShare_ProductSerialNumber.Value
              REC_BsShare_SMTManufacturingDate_Value: accessed-variable=BsShare_SMTManufacturingDate.Value
              REC_BsShare_SMTPlantNumber_Value: accessed-variable=BsShare_SMTPlantNumber.Value
              REC_BsShare_SwUpdFotaFinPrint_Element_Value: accessed-variable=BsShare_SwUpdFotaFinPrint_Element.Value
              REC_BsShare_SwUpdFotaMode_Element_Value: accessed-variable=BsShare_SwUpdFotaMode_Element.Value
              REC_BsShare_SwUpdFotaStatus_Element_Value: accessed-variable=BsShare_SwUpdFotaStatus_Element.Value
              REC_BsShare_SwUpdFotadecrypt_Element_Value: accessed-variable=BsShare_SwUpdFotadecrypt_Element.Value
              REC_BsShare_SwUpdReflash_Element_Value: accessed-variable=BsShare_SwUpdReflash_Element.Value
              REC_BsShare_VehicleConfig_Element_Value: accessed-variable=BsShare_VehicleConfig_Element.Value
              REC_BsShare_VisMeet_EOLEntry_Element_Value: accessed-variable=BsShare_VisMeet_EOLEntry_Element.Value
              REC_BsShare_VisMeet_Element_Value: accessed-variable=BsShare_VisMeet_Element.Value
              REC_BsShare_VisteonPCBPartNumber_Value: accessed-variable=BsShare_VisteonPCBPartNumber.Value
              REC_BsShare_VisteonPartNumber_Value: accessed-variable=BsShare_VisteonPartNumber.Value
              REC_RefCys_Certicificate1_Element_Value: accessed-variable=RefCys_Certicificate1_Element.Value
              REC_RefCys_Certicificate_Element_Value: accessed-variable=RefCys_Certicificate_Element.Value
          data-send-points:
            94 x access:
              SEND_BsConst_Audio_Element_Value: accessed-variable=BsConst_Audio_Element.Value
              SEND_BsConst_BsConst_Illumination_ReservedByte_Value: accessed-variable=BsConst_BsConst_Illumination_ReservedByte.Value
              SEND_BsConst_BsConst_Illumination_ReservedByte_SafeCopy1_Value: accessed-variable=BsConst_BsConst_Illumination_ReservedByte_SafeCopy1.Value
              SEND_BsConst_BsConst_Illumination_ReservedByte_SafeCopy2_Value: accessed-variable=BsConst_BsConst_Illumination_ReservedByte_SafeCopy2.Value
              SEND_BsConst_Communication_Element_Value: accessed-variable=BsConst_Communication_Element.Value
              SEND_BsConst_Compensation_Line_Shift_b_Value: accessed-variable=BsConst_Compensation_Line_Shift_b.Value
              SEND_BsConst_Compensation_Line_Shift_b_SafeCopy1_Value: accessed-variable=BsConst_Compensation_Line_Shift_b_SafeCopy1.Value
              SEND_BsConst_Compensation_Line_Shift_b_SafeCopy2_Value: accessed-variable=BsConst_Compensation_Line_Shift_b_SafeCopy2.Value
              SEND_BsConst_Compensation_Line_Slope_m_Value: accessed-variable=BsConst_Compensation_Line_Slope_m.Value
              SEND_BsConst_Compensation_Line_Slope_m_SafeCopy1_Value: accessed-variable=BsConst_Compensation_Line_Slope_m_SafeCopy1.Value
              SEND_BsConst_Compensation_Line_Slope_m_SafeCopy2_Value: accessed-variable=BsConst_Compensation_Line_Slope_m_SafeCopy2.Value
              SEND_BsConst_Derating_Backlight_Disable_Value: accessed-variable=BsConst_Derating_Backlight_Disable.Value
              SEND_BsConst_Derating_Backlight_Disable_SafeCopy1_Value: accessed-variable=BsConst_Derating_Backlight_Disable_SafeCopy1.Value
              SEND_BsConst_Derating_Backlight_Disable_SafeCopy2_Value: accessed-variable=BsConst_Derating_Backlight_Disable_SafeCopy2.Value
              SEND_BsConst_Display_Illum_Max_Level_Value: accessed-variable=BsConst_Display_Illum_Max_Level.Value
              SEND_BsConst_Display_Illum_Max_Level_SafeCopy1_Value: accessed-variable=BsConst_Display_Illum_Max_Level_SafeCopy1.Value
              SEND_BsConst_Display_Illum_Max_Level_SafeCopy2_Value: accessed-variable=BsConst_Display_Illum_Max_Level_SafeCopy2.Value
              SEND_BsConst_EngOffTimer_Element_Value: accessed-variable=BsConst_EngOffTimer_Element.Value
              SEND_BsConst_FuelGauge_Element_Value: accessed-variable=BsConst_FuelGauge_Element.Value
              SEND_BsConst_Lookup_Curve_HotSpot_Coef_X_Value: accessed-variable=BsConst_Lookup_Curve_HotSpot_Coef_X.Value
              SEND_BsConst_Lookup_Curve_HotSpot_Coef_X_SafeCopy1_Value: accessed-variable=BsConst_Lookup_Curve_HotSpot_Coef_X_SafeCopy1.Value
              SEND_BsConst_Lookup_Curve_HotSpot_Coef_X_SafeCopy2_Value: accessed-variable=BsConst_Lookup_Curve_HotSpot_Coef_X_SafeCopy2.Value
              SEND_BsConst_Lookup_Curve_HotSpot_Coef_Y_Value: accessed-variable=BsConst_Lookup_Curve_HotSpot_Coef_Y.Value
              SEND_BsConst_Lookup_Curve_HotSpot_Coef_Y_SafeCopy1_Value: accessed-variable=BsConst_Lookup_Curve_HotSpot_Coef_Y_SafeCopy1.Value
              SEND_BsConst_Lookup_Curve_HotSpot_Coef_Y_SafeCopy2_Value: accessed-variable=BsConst_Lookup_Curve_HotSpot_Coef_Y_SafeCopy2.Value
              SEND_BsConst_OilGauge_Element_Value: accessed-variable=BsConst_OilGauge_Element.Value
              SEND_BsConst_PCB_Temperature_Sensor_Conv_Value: accessed-variable=BsConst_PCB_Temperature_Sensor_Conv.Value
              SEND_BsConst_PCB_Temperature_Sensor_Conv_SafeCopy1_Value: accessed-variable=BsConst_PCB_Temperature_Sensor_Conv_SafeCopy1.Value
              SEND_BsConst_PCB_Temperature_Sensor_Conv_SafeCopy2_Value: accessed-variable=BsConst_PCB_Temperature_Sensor_Conv_SafeCopy2.Value
              SEND_BsConst_PWM_boost_bypass_duty_Value: accessed-variable=BsConst_PWM_boost_bypass_duty.Value
              SEND_BsConst_PWM_boost_bypass_duty_SafeCopy1_Value: accessed-variable=BsConst_PWM_boost_bypass_duty_SafeCopy1.Value
              SEND_BsConst_PWM_boost_bypass_duty_SafeCopy2_Value: accessed-variable=BsConst_PWM_boost_bypass_duty_SafeCopy2.Value
              SEND_BsConst_PowerGauge_Element_Value: accessed-variable=BsConst_PowerGauge_Element.Value
              SEND_BsConst_Power_Element_Value: accessed-variable=BsConst_Power_Element.Value
              SEND_BsConst_RealTimeClock_Element_Value: accessed-variable=BsConst_RealTimeClock_Element.Value
              SEND_BsConst_ServiceReminder_Element_Value: accessed-variable=BsConst_ServiceReminder_Element.Value
              SEND_BsConst_SpeedoGauge_Element_Value: accessed-variable=BsConst_SpeedoGauge_Element.Value
              SEND_BsConst_TachoGauge_Element_Value: accessed-variable=BsConst_TachoGauge_Element.Value
              SEND_BsConst_TempGauge_Element_Value: accessed-variable=BsConst_TempGauge_Element.Value
              SEND_BsConst_Temp_Threshold_Hysteresis_Derating_Value: accessed-variable=BsConst_Temp_Threshold_Hysteresis_Derating.Value
              SEND_BsConst_Temp_Threshold_Hysteresis_Derating_SafeCopy1_Value: accessed-variable=BsConst_Temp_Threshold_Hysteresis_Derating_SafeCopy1.Value
              SEND_BsConst_Temp_Threshold_Hysteresis_Derating_SafeCopy2_Value: accessed-variable=BsConst_Temp_Threshold_Hysteresis_Derating_SafeCopy2.Value
              SEND_BsConst_Temperature_Sensor_Conv_Value: accessed-variable=BsConst_Temperature_Sensor_Conv.Value
              SEND_BsConst_Temperature_Sensor_Conv_SafeCopy1_Value: accessed-variable=BsConst_Temperature_Sensor_Conv_SafeCopy1.Value
              SEND_BsConst_Temperature_Sensor_Conv_SafeCopy2_Value: accessed-variable=BsConst_Temperature_Sensor_Conv_SafeCopy2.Value
              SEND_BsConst_TripComputer_Element_Value: accessed-variable=BsConst_TripComputer_Element.Value
              SEND_BsConst_Warning_Element_Value: accessed-variable=BsConst_Warning_Element.Value
              SEND_BsCys_Certicificate_Element_Value: accessed-variable=BsCys_Certicificate_Element.Value
              SEND_BsDiag_Dtc_Element_Value: accessed-variable=BsDiag_Dtc_Element.Value
              SEND_BsDiag_ErrorRecord_Element_Value: accessed-variable=BsDiag_ErrorRecord_Element.Value
              SEND_BsReten_Audio_Element_Value: accessed-variable=BsReten_Audio_Element.Value
              SEND_BsReten_Communication_Element_Value: accessed-variable=BsReten_Communication_Element.Value
              SEND_BsReten_Display_Element_Value: accessed-variable=BsReten_Display_Element.Value
              SEND_BsReten_Gauges_Element_Value: accessed-variable=BsReten_Gauges_Element.Value
              SEND_BsReten_Illumination_Element_Value: accessed-variable=BsReten_Illumination_Element.Value
              SEND_BsReten_Odometer_Element_Value: accessed-variable=BsReten_Odometer_Element.Value
              SEND_BsReten_Personalization_Element_Value: accessed-variable=BsReten_Personalization_Element.Value
              SEND_BsReten_Power_Element_Value: accessed-variable=BsReten_Power_Element.Value
              SEND_BsReten_RealTimeClock_Element_Value: accessed-variable=BsReten_RealTimeClock_Element.Value
              SEND_BsReten_Tripcomputer_Element_Value: accessed-variable=BsReten_Tripcomputer_Element.Value
              SEND_BsReten_Warning_Element_Value: accessed-variable=BsReten_Warning_Element.Value
              SEND_BsRt_CusDlt_Element_Value: accessed-variable=BsRt_CusDlt_Element.Value
              SEND_BsRt_FuelGauge_Element_Value: accessed-variable=BsRt_FuelGauge_Element.Value
              SEND_BsRt_Illumination_Element_Value: accessed-variable=BsRt_Illumination_Element.Value
              SEND_BsRt_Odometer_Element_Value: accessed-variable=BsRt_Odometer_Element.Value
              SEND_BsRt_OilGauge_Element_Value: accessed-variable=BsRt_OilGauge_Element.Value
              SEND_BsRt_Personalization_Element_Value: accessed-variable=BsRt_Personalization_Element.Value
              SEND_BsRt_PowerGauge_Element_Value: accessed-variable=BsRt_PowerGauge_Element.Value
              SEND_BsRt_RealTimeClock_Element_Value: accessed-variable=BsRt_RealTimeClock_Element.Value
              SEND_BsRt_SpeedoGauge_Element_Value: accessed-variable=BsRt_SpeedoGauge_Element.Value
              SEND_BsRt_TachoGauge_Element_Value: accessed-variable=BsRt_TachoGauge_Element.Value
              SEND_BsRt_TempGauge_Element_Value: accessed-variable=BsRt_TempGauge_Element.Value
              SEND_BsRt_TripComputer_Element_Value: accessed-variable=BsRt_TripComputer_Element.Value
              SEND_BsRt_Warning_Element_Value: accessed-variable=BsRt_Warning_Element.Value
              SEND_BsShare_AssemblyManufacturingDate_Value: accessed-variable=BsShare_AssemblyManufacturingDate.Value
              SEND_BsShare_AssemblyPlantNumber_Value: accessed-variable=BsShare_AssemblyPlantNumber.Value
              SEND_BsShare_EcuPartNumber_Element_Value: accessed-variable=BsShare_EcuPartNumber_Element.Value
              SEND_BsShare_HWModification_Value: accessed-variable=BsShare_HWModification.Value
              SEND_BsShare_PCBSerialNumber_Value: accessed-variable=BsShare_PCBSerialNumber.Value
              SEND_BsShare_ProductSerialNumber_Value: accessed-variable=BsShare_ProductSerialNumber.Value
              SEND_BsShare_SMTManufacturingDate_Value: accessed-variable=BsShare_SMTManufacturingDate.Value
              SEND_BsShare_SMTPlantNumber_Value: accessed-variable=BsShare_SMTPlantNumber.Value
              SEND_BsShare_SwUpdFotaFinPrint_Element_Value: accessed-variable=BsShare_SwUpdFotaFinPrint_Element.Value
              SEND_BsShare_SwUpdFotaMode_Element_Value: accessed-variable=BsShare_SwUpdFotaMode_Element.Value
              SEND_BsShare_SwUpdFotaStatus_Element_Value: accessed-variable=BsShare_SwUpdFotaStatus_Element.Value
              SEND_BsShare_SwUpdFotadecrypt_Element_Value: accessed-variable=BsShare_SwUpdFotadecrypt_Element.Value
              SEND_BsShare_SwUpdReflash_Element_Value: accessed-variable=BsShare_SwUpdReflash_Element.Value
              SEND_BsShare_VehicleConfig_Element_Value: accessed-variable=BsShare_VehicleConfig_Element.Value
              SEND_BsShare_VisMeet_EOLEntry_Element_Value: accessed-variable=BsShare_VisMeet_EOLEntry_Element.Value
              SEND_BsShare_VisMeet_Element_Value: accessed-variable=BsShare_VisMeet_Element.Value
              SEND_BsShare_VisteonPCBPartNumber_Value: accessed-variable=BsShare_VisteonPCBPartNumber.Value
              SEND_BsShare_VisteonPartNumber_Value: accessed-variable=BsShare_VisteonPartNumber.Value
              SEND_RefCys_Certicificate1_Element_Value: accessed-variable=RefCys_Certicificate1_Element.Value
              SEND_RefCys_Certicificate_Element_Value: accessed-variable=RefCys_Certicificate_Element.Value
        MemAbstractMdl_NotifyJobEnd_BsConst_Audio
        MemAbstractMdl_NotifyJobEnd_BsConst_Communication
        MemAbstractMdl_NotifyJobEnd_BsConst_EngOffTimer
        MemAbstractMdl_NotifyJobEnd_BsConst_FuelGauge
        MemAbstractMdl_NotifyJobEnd_BsConst_OilGauge
        MemAbstractMdl_NotifyJobEnd_BsConst_Power
        MemAbstractMdl_NotifyJobEnd_BsConst_PowerGauge
        MemAbstractMdl_NotifyJobEnd_BsConst_RealTimeClock
        MemAbstractMdl_NotifyJobEnd_BsConst_ServiceReminder
        MemAbstractMdl_NotifyJobEnd_BsConst_SpeedoGauge
        MemAbstractMdl_NotifyJobEnd_BsConst_TachoGauge
        MemAbstractMdl_NotifyJobEnd_BsConst_TempGauge
        MemAbstractMdl_NotifyJobEnd_BsConst_TripComputer
        MemAbstractMdl_NotifyJobEnd_BsConst_Warning
        MemAbstractMdl_NotifyJobEnd_BsCys_Certicificate
        MemAbstractMdl_NotifyJobEnd_BsDiag_Dtc
        MemAbstractMdl_NotifyJobEnd_BsDiag_ErrorRecord
        MemAbstractMdl_NotifyJobEnd_BsReten_Audio
        MemAbstractMdl_NotifyJobEnd_BsReten_Communication
        MemAbstractMdl_NotifyJobEnd_BsReten_Display
        MemAbstractMdl_NotifyJobEnd_BsReten_Gauges
        MemAbstractMdl_NotifyJobEnd_BsReten_Illumination
        MemAbstractMdl_NotifyJobEnd_BsReten_Odometer
        MemAbstractMdl_NotifyJobEnd_BsReten_Personalization
        MemAbstractMdl_NotifyJobEnd_BsReten_Power
        MemAbstractMdl_NotifyJobEnd_BsReten_RealTimeClock
        MemAbstractMdl_NotifyJobEnd_BsReten_Tripcomputer
        MemAbstractMdl_NotifyJobEnd_BsReten_Warning
        MemAbstractMdl_NotifyJobEnd_BsRt_CusDlt
        MemAbstractMdl_NotifyJobEnd_BsRt_FuelGauge
        MemAbstractMdl_NotifyJobEnd_BsRt_Illumination
        MemAbstractMdl_NotifyJobEnd_BsRt_Odometer
        MemAbstractMdl_NotifyJobEnd_BsRt_OilGauge
        MemAbstractMdl_NotifyJobEnd_BsRt_Personalization
        MemAbstractMdl_NotifyJobEnd_BsRt_PowerGauge
        MemAbstractMdl_NotifyJobEnd_BsRt_RealTimeClock
        MemAbstractMdl_NotifyJobEnd_BsRt_SpeedoGauge
        MemAbstractMdl_NotifyJobEnd_BsRt_TachoGauge
        MemAbstractMdl_NotifyJobEnd_BsRt_TempGauge
        MemAbstractMdl_NotifyJobEnd_BsRt_TripComputer
        MemAbstractMdl_NotifyJobEnd_BsRt_Warning
        MemAbstractMdl_NotifyJobEnd_BsShare_EcuPartNumber
        MemAbstractMdl_NotifyJobEnd_BsShare_SwUpdFotaFinPrint
        MemAbstractMdl_NotifyJobEnd_BsShare_SwUpdFotaMode
        MemAbstractMdl_NotifyJobEnd_BsShare_SwUpdFotaStatus
        MemAbstractMdl_NotifyJobEnd_BsShare_SwUpdFotadecrypt
        MemAbstractMdl_NotifyJobEnd_BsShare_SwUpdReflash
        MemAbstractMdl_NotifyJobEnd_BsShare_VehicleConfig
        MemAbstractMdl_NotifyJobEnd_BsShare_VisMeet
        MemAbstractMdl_NotifyJobEnd_RefCys_Certicificate
        MemAbstractMdl_NotifyJobEnd_RefCys_Certicificate1
  swc implementation MemAbstractStub_Implementation: behavior=MemAbstractStub_InternalBehavior
    code-descriptors:
      code Default: artifact-descriptors=autosar-engineering-object=category=SWSRC
